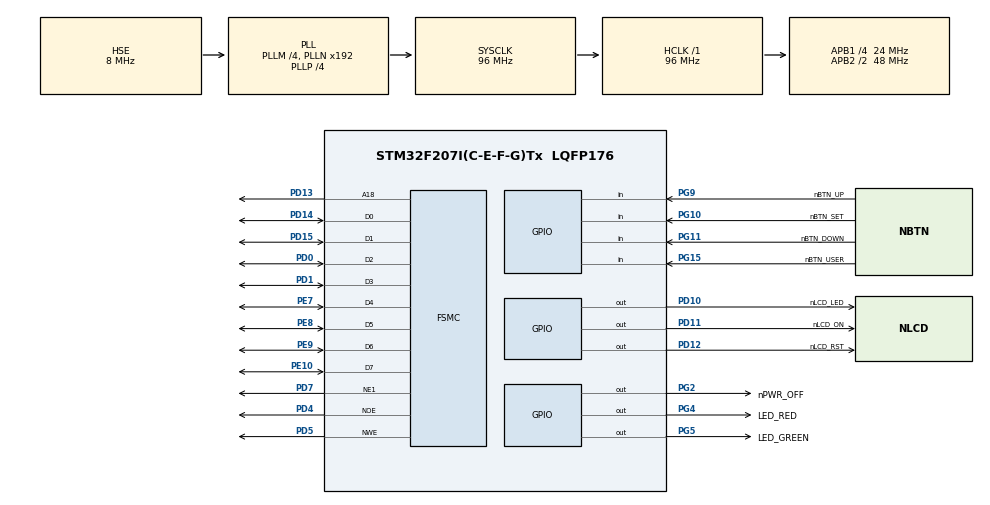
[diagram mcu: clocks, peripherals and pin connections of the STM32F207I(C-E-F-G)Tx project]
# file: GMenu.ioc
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FREERTOS.HEAP_NUMBER=4
FREERTOS.Tasks01=TaskInit,0,1024,InitShell,Default,NULL,Dynamic,NULL,NULL
FREERTOS.configCHECK_FOR_STACK_OVERFLOW=2
FREERTOS.configTOTAL_HEAP_SIZE=32768
FREERTOS.configUSE_COUNTING_SEMAPHORES=1
FREERTOS.configUSE_MALLOC_FAILED_HOOK=1
FSMC.AddressSetupTime1=15
FSMC.BusTurnAroundDuration1=15
Mcu.Family=STM32F2
Mcu.Name=STM32F207I(C-E-F-G)Tx
Mcu.Package=LQFP176
NVIC.PriorityGroup=NVIC_PRIORITYGROUP_4
NVIC.TIM1_UP_TIM10_IRQn=true\:0\:0\:false\:false\:true\:false\:false\:true
NVIC.TimeBase=TIM1_UP_TIM10_IRQn
NVIC.TimeBaseIP=TIM1
PA13.Mode=Serial_Wire
PA13.Signal=SYS_JTMS-SWDIO
PA14.Mode=Serial_Wire
PA14.Signal=SYS_JTCK-SWCLK
PC14-OSC32_IN.Mode=LSE-External-Oscillator
PC14-OSC32_IN.Signal=RCC_OSC32_IN
PC15-OSC32_OUT.Mode=LSE-External-Oscillator
PC15-OSC32_OUT.Signal=RCC_OSC32_OUT
PD0.Signal=FSMC_D2_DA2
PD1.Signal=FSMC_D3_DA3
PD10.GPIO_Label=nLCD_LED
PD10.PinState=GPIO_PIN_SET
PD10.Signal=GPIO_Output
PD11.GPIO_Label=nLCD_ON
PD11.PinState=GPIO_PIN_RESET
PD11.Signal=GPIO_Output
PD12.GPIO_Label=nLCD_RST
PD12.Signal=GPIO_Output
PD13.Signal=FSMC_A18
PD14.Signal=FSMC_D0_DA0
PD15.Signal=FSMC_D1_DA1
PD4.Signal=FSMC_NOE
PD5.Signal=FSMC_NWE
PD7.Mode=NorPsramChipSelect1_1
PD7.Signal=FSMC_NE1
PE10.Signal=FSMC_D7_DA7
PE7.Signal=FSMC_D4_DA4
PE8.Signal=FSMC_D5_DA5
PE9.Signal=FSMC_D6_DA6
PG10.GPIO_Label=nBTN_SET
PG10.GPIO_PuPd=GPIO_PULLUP
PG10.Signal=GPIO_Input
PG11.GPIO_Label=nBTN_DOWN
PG11.GPIO_PuPd=GPIO_PULLUP
PG11.Signal=GPIO_Input
PG15.GPIO_Label=nBTN_USER
PG15.GPIO_PuPd=GPIO_PULLUP
PG15.Signal=GPIO_Input
PG2.GPIO_Label=nPWR_OFF
PG2.GPIO_PuPd=GPIO_NOPULL
PG2.PinState=GPIO_PIN_SET
PG2.Signal=GPIO_Output
PG4.GPIO_Label=LED_RED
PG4.GPIO_PuPd=GPIO_NOPULL
PG4.Signal=GPIO_Output
PG5.GPIO_Label=LED_GREEN
PG5.GPIO_PuPd=GPIO_NOPULL
PG5.PinState=GPIO_PIN_SET
PG5.Signal=GPIO_Output
PG9.GPIO_Label=nBTN_UP
PG9.GPIO_PuPd=GPIO_PULLUP
PG9.Signal=GPIO_Input
PH0-OSC_IN.Mode=HSE-External-Oscillator
PH0-OSC_IN.Signal=RCC_OSC_IN
PH1-OSC_OUT.Mode=HSE-External-Oscillator
PH1-OSC_OUT.Signal=RCC_OSC_OUT
ProjectManager.HeapSize=0x200
ProjectManager.StackSize=0x400
ProjectManager.TargetToolchain=MDK-ARM V5
RCC.48MHZClocksFreq_Value=96000000
RCC.AHBFreq_Value=96000000
RCC.APB1CLKDivider=RCC_HCLK_DIV4
RCC.APB1Freq_Value=24000000
RCC.APB1TimFreq_Value=48000000
RCC.APB2CLKDivider=RCC_HCLK_DIV2
RCC.APB2Freq_Value=48000000
RCC.APB2TimFreq_Value=96000000
RCC.CortexFreq_Value=96000000
RCC.HCLKFreq_Value=96000000
RCC.HSE_VALUE=8000000
RCC.HSI_VALUE=16000000
RCC.PLLM=4
RCC.PLLP=RCC_PLLP_DIV4
RCC.PLLSourceVirtual=RCC_PLLSOURCE_HSE
RCC.RCC_RTC_Clock_Source=RCC_RTCCLKSOURCE_LSE
RCC.RCC_RTC_Clock_SourceVirtual=RCC_RTCCLKSOURCE_LSE
RCC.SYSCLKFreq_VALUE=96000000
RCC.SYSCLKSource=RCC_SYSCLKSOURCE_PLLCLK
RCC.VCOOutputFreq_Value=384000000
RTC.Date=26
RTC.Format=RTC_FORMAT_BCD
RTC.Hours=15
RTC.Minutes=33
RTC.Month=RTC_MONTH_JULY
RTC.Seconds=15
RTC.WeekDay=RTC_WEEKDAY_FRIDAY
RTC.Year=19
SH.FSMC_A18.0=FSMC_A18,A18_1
SH.FSMC_D0_DA0.0=FSMC_D0,8b-d1
SH.FSMC_D1_DA1.0=FSMC_D1,8b-d1
SH.FSMC_D2_DA2.0=FSMC_D2,8b-d1
SH.FSMC_D3_DA3.0=FSMC_D3,8b-d1
SH.FSMC_D4_DA4.0=FSMC_D4,8b-d1
SH.FSMC_D5_DA5.0=FSMC_D5,8b-d1
SH.FSMC_D6_DA6.0=FSMC_D6,8b-d1
SH.FSMC_D7_DA7.0=FSMC_D7,8b-d1
SH.FSMC_NOE.0=FSMC_NOE,Lcd1
SH.FSMC_NWE.0=FSMC_NWE,Lcd1
VP_FREERTOS_VS_CMSIS_V1.Mode=CMSIS_V1
VP_RTC_VS_RTC_Activate.Mode=RTC_Enabled
VP_RTC_VS_RTC_Calendar.Mode=RTC_Calendar
VP_SYS_VS_tim1.Mode=TIM1
board=custom

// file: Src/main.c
/* USER CODE BEGIN Header */
/**
  ******************************************************************************
  * @file           : main.c
  * @brief          : Main program body
  ******************************************************************************
  * @attention
  *
  * <h2><center>&copy; Copyright (c) 2019 STMicroelectronics.
  * All rights reserved.</center></h2>
  *
  * This software component is licensed by ST under Ultimate Liberty license
  * SLA0044, the "License"; You may not use this file except in compliance with
  * the License. You may obtain a copy of the License at:
  *                             www.st.com/SLA0044
  *
  ******************************************************************************
  */
/* USER CODE END Header */

#include "main.h"
#include "cmsis_os.h"

/* USER CODE BEGIN Includes */

#include "my_main.h"
#include "tm_stm32_button.h"

/* USER CODE END Includes */

/* USER CODE BEGIN PTD */

#include "ecg.h"
#include "hooks.h"

/* USER CODE END PTD */

RTC_HandleTypeDef hrtc;

SRAM_HandleTypeDef hsram1;

osThreadId TaskInitHandle;

void SystemClock_Config(void);
static void MX_GPIO_Init(void);
static void MX_FSMC_Init(void);
static void MX_RTC_Init(void);
void InitShell(void const * argument);

int main(void)
{

  /* MCU Configuration--------------------------------------------------------*/

  /* Reset of all peripherals, Initializes the Flash interface and the Systick. */
  HAL_Init();

  /* Configure the system clock */
  SystemClock_Config();

  /* Initialize all configured peripherals */
  MX_GPIO_Init();
  MX_FSMC_Init();
  MX_RTC_Init();
  /* USER CODE BEGIN 2 */

  EcgInit();

  /* USER CODE END 2 */

  /* Create the thread(s) */
  /* definition and creation of TaskInit */
  osThreadDef(TaskInit, InitShell, osPriorityNormal, 0, 1024);
  TaskInitHandle = osThreadCreate(osThread(TaskInit), NULL);

  /* Start scheduler */
  osKernelStart();

  /* We should never get here as control is now taken by the scheduler */

  /* Infinite loop */
  while (1)
  {

  }
}

void SystemClock_Config(void)
{
  RCC_OscInitTypeDef RCC_OscInitStruct = {0};
  RCC_ClkInitTypeDef RCC_ClkInitStruct = {0};
  RCC_PeriphCLKInitTypeDef PeriphClkInitStruct = {0};

  /** Initializes the CPU, AHB and APB busses clocks
  */
  RCC_OscInitStruct.OscillatorType = RCC_OSCILLATORTYPE_HSE|RCC_OSCILLATORTYPE_LSE;
  RCC_OscInitStruct.HSEState = RCC_HSE_ON;
  RCC_OscInitStruct.LSEState = RCC_LSE_ON;
  RCC_OscInitStruct.PLL.PLLState = RCC_PLL_ON;
  RCC_OscInitStruct.PLL.PLLSource = RCC_PLLSOURCE_HSE;
  RCC_OscInitStruct.PLL.PLLM = 4;
  RCC_OscInitStruct.PLL.PLLN = 192;
  RCC_OscInitStruct.PLL.PLLP = RCC_PLLP_DIV4;
  RCC_OscInitStruct.PLL.PLLQ = 4;
  if (HAL_RCC_OscConfig(&RCC_OscInitStruct) != HAL_OK)
  {
    Error_Handler();
  }
  /** Initializes the CPU, AHB and APB busses clocks
  */
  RCC_ClkInitStruct.ClockType = RCC_CLOCKTYPE_HCLK|RCC_CLOCKTYPE_SYSCLK
                              |RCC_CLOCKTYPE_PCLK1|RCC_CLOCKTYPE_PCLK2;
  RCC_ClkInitStruct.SYSCLKSource = RCC_SYSCLKSOURCE_PLLCLK;
  RCC_ClkInitStruct.AHBCLKDivider = RCC_SYSCLK_DIV1;
  RCC_ClkInitStruct.APB1CLKDivider = RCC_HCLK_DIV4;
  RCC_ClkInitStruct.APB2CLKDivider = RCC_HCLK_DIV2;

  if (HAL_RCC_ClockConfig(&RCC_ClkInitStruct, FLASH_LATENCY_3) != HAL_OK)
  {
    Error_Handler();
  }
  PeriphClkInitStruct.PeriphClockSelection = RCC_PERIPHCLK_RTC;
  PeriphClkInitStruct.RTCClockSelection = RCC_RTCCLKSOURCE_LSE;
  if (HAL_RCCEx_PeriphCLKConfig(&PeriphClkInitStruct) != HAL_OK)
  {
    Error_Handler();
  }
}

static void MX_RTC_Init(void)
{

  RTC_TimeTypeDef sTime = {0};
  RTC_DateTypeDef sDate = {0};

  /** Initialize RTC Only
  */
  hrtc.Instance = RTC;
  hrtc.Init.HourFormat = RTC_HOURFORMAT_24;
  hrtc.Init.AsynchPrediv = 127;
  hrtc.Init.SynchPrediv = 255;
  hrtc.Init.OutPut = RTC_OUTPUT_DISABLE;
  hrtc.Init.OutPutPolarity = RTC_OUTPUT_POLARITY_HIGH;
  hrtc.Init.OutPutType = RTC_OUTPUT_TYPE_OPENDRAIN;
  if (HAL_RTC_Init(&hrtc) != HAL_OK)
  {
    Error_Handler();
  }

  /** Initialize RTC and set the Time and Date
  */
  sTime.Hours = 0x15;
  sTime.Minutes = 0x33;
  sTime.Seconds = 0x15;
  sTime.DayLightSaving = RTC_DAYLIGHTSAVING_NONE;
  sTime.StoreOperation = RTC_STOREOPERATION_RESET;
  if (HAL_RTC_SetTime(&hrtc, &sTime, RTC_FORMAT_BCD) != HAL_OK)
  {
    Error_Handler();
  }
  sDate.WeekDay = RTC_WEEKDAY_FRIDAY;
  sDate.Month = RTC_MONTH_JULY;
  sDate.Date = 0x26;
  sDate.Year = 0x19;

  if (HAL_RTC_SetDate(&hrtc, &sDate, RTC_FORMAT_BCD) != HAL_OK)
  {
    Error_Handler();
  }

}

static void MX_GPIO_Init(void)
{
  GPIO_InitTypeDef GPIO_InitStruct = {0};

  /* GPIO Ports Clock Enable */
  __HAL_RCC_GPIOC_CLK_ENABLE();
  __HAL_RCC_GPIOH_CLK_ENABLE();
  __HAL_RCC_GPIOE_CLK_ENABLE();
  __HAL_RCC_GPIOD_CLK_ENABLE();
  __HAL_RCC_GPIOG_CLK_ENABLE();
  __HAL_RCC_GPIOA_CLK_ENABLE();

  /*Configure GPIO pin Output Level */
  HAL_GPIO_WritePin(nLCD_LED_GPIO_Port, nLCD_LED_Pin, GPIO_PIN_SET);

  /*Configure GPIO pin Output Level */
  HAL_GPIO_WritePin(GPIOD, nLCD_ON_Pin|nLCD_RST_Pin, GPIO_PIN_RESET);

  /*Configure GPIO pin Output Level */
  HAL_GPIO_WritePin(GPIOG, nPWR_OFF_Pin|LED_GREEN_Pin, GPIO_PIN_SET);

  /*Configure GPIO pin Output Level */
  HAL_GPIO_WritePin(LED_RED_GPIO_Port, LED_RED_Pin, GPIO_PIN_RESET);

  /*Configure GPIO pins : nLCD_LED_Pin nLCD_ON_Pin nLCD_RST_Pin */
  GPIO_InitStruct.Pin = nLCD_LED_Pin|nLCD_ON_Pin|nLCD_RST_Pin;
  GPIO_InitStruct.Mode = GPIO_MODE_OUTPUT_PP;
  GPIO_InitStruct.Pull = GPIO_NOPULL;
  GPIO_InitStruct.Speed = GPIO_SPEED_FREQ_LOW;
  HAL_GPIO_Init(GPIOD, &GPIO_InitStruct);

  /*Configure GPIO pins : nPWR_OFF_Pin LED_RED_Pin LED_GREEN_Pin */
  GPIO_InitStruct.Pin = nPWR_OFF_Pin|LED_RED_Pin|LED_GREEN_Pin;
  GPIO_InitStruct.Mode = GPIO_MODE_OUTPUT_PP;
  GPIO_InitStruct.Pull = GPIO_NOPULL;
  GPIO_InitStruct.Speed = GPIO_SPEED_FREQ_LOW;
  HAL_GPIO_Init(GPIOG, &GPIO_InitStruct);

  /*Configure GPIO pins : nBTN_UP_Pin nBTN_SET_Pin nBTN_DOWN_Pin nBTN_USER_Pin */
  GPIO_InitStruct.Pin = nBTN_UP_Pin|nBTN_SET_Pin|nBTN_DOWN_Pin|nBTN_USER_Pin;
  GPIO_InitStruct.Mode = GPIO_MODE_INPUT;
  GPIO_InitStruct.Pull = GPIO_PULLUP;
  HAL_GPIO_Init(GPIOG, &GPIO_InitStruct);

}

/* FSMC initialization function */
static void MX_FSMC_Init(void)
{

  FSMC_NORSRAM_TimingTypeDef Timing = {0};

  /** Perform the SRAM1 memory initialization sequence
  */
  hsram1.Instance = FSMC_NORSRAM_DEVICE;
  hsram1.Extended = FSMC_NORSRAM_EXTENDED_DEVICE;
  /* hsram1.Init */
  hsram1.Init.NSBank = FSMC_NORSRAM_BANK1;
  hsram1.Init.DataAddressMux = FSMC_DATA_ADDRESS_MUX_DISABLE;
  hsram1.Init.MemoryType = FSMC_MEMORY_TYPE_SRAM;
  hsram1.Init.MemoryDataWidth = FSMC_NORSRAM_MEM_BUS_WIDTH_8;
  hsram1.Init.BurstAccessMode = FSMC_BURST_ACCESS_MODE_DISABLE;
  hsram1.Init.WaitSignalPolarity = FSMC_WAIT_SIGNAL_POLARITY_LOW;
  hsram1.Init.WrapMode = FSMC_WRAP_MODE_DISABLE;
  hsram1.Init.WaitSignalActive = FSMC_WAIT_TIMING_BEFORE_WS;
  hsram1.Init.WriteOperation = FSMC_WRITE_OPERATION_ENABLE;
  hsram1.Init.WaitSignal = FSMC_WAIT_SIGNAL_DISABLE;
  hsram1.Init.ExtendedMode = FSMC_EXTENDED_MODE_DISABLE;
  hsram1.Init.AsynchronousWait = FSMC_ASYNCHRONOUS_WAIT_DISABLE;
  hsram1.Init.WriteBurst = FSMC_WRITE_BURST_DISABLE;
  /* Timing */
  Timing.AddressSetupTime = 15;
  Timing.AddressHoldTime = 15;
  Timing.DataSetupTime = 255;
  Timing.BusTurnAroundDuration = 15;
  Timing.CLKDivision = 16;
  Timing.DataLatency = 17;
  Timing.AccessMode = FSMC_ACCESS_MODE_A;
  /* ExtTiming */

  if (HAL_SRAM_Init(&hsram1, &Timing, NULL) != HAL_OK)
  {
    Error_Handler( );
  }

}

void InitShell(void const * argument)
{

  /* USER CODE BEGIN 5 */
  /* Infinite loop */
  while (1)
  {
    MyInit();
    vTaskDelete(TaskInitHandle);
  }
  /* USER CODE END 5 */
}

void HAL_TIM_PeriodElapsedCallback(TIM_HandleTypeDef *htim)
{
  if (htim->Instance == TIM1) {
    HAL_IncTick();
  }
}

void Error_Handler(void)
{
}

/************************ (C) COPYRIGHT STMicroelectronics *****END OF FILE****/
